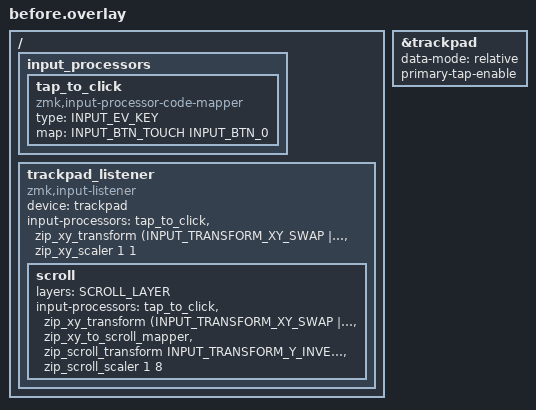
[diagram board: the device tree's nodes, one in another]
#include <input/processors.dtsi>
#include <zephyr/dt-bindings/input/input-event-codes.h>
#include <dt-bindings/zmk/input_transform.h>

#define SCROLL_LAYER 2

&trackpad {
    data-mode = "relative";
    primary-tap-enable;
};

/ {
    input_processors {
        tap_to_click: tap_to_click {
            compatible = "zmk,input-processor-code-mapper";
            #input-processor-cells = <0>;
            type = <INPUT_EV_KEY>;
            map = <INPUT_BTN_TOUCH INPUT_BTN_0>;
        };
    };

    trackpad_listener: trackpad_listener {
        compatible = "zmk,input-listener";
        device = <&trackpad>;
        input-processors = <&tap_to_click>,
                           <&zip_xy_transform (INPUT_TRANSFORM_XY_SWAP | INPUT_TRANSFORM_Y_INVERT)>,
                           <&zip_xy_scaler 1 1>;

        scroll {
            layers = <SCROLL_LAYER>;
            input-processors = <&tap_to_click>,
                               <&zip_xy_transform (INPUT_TRANSFORM_XY_SWAP | INPUT_TRANSFORM_Y_INVERT)>,
                               <&zip_xy_to_scroll_mapper>,
                               <&zip_scroll_transform INPUT_TRANSFORM_Y_INVERT>,
                               <&zip_scroll_scaler 1 8>;
        };
    };
};
